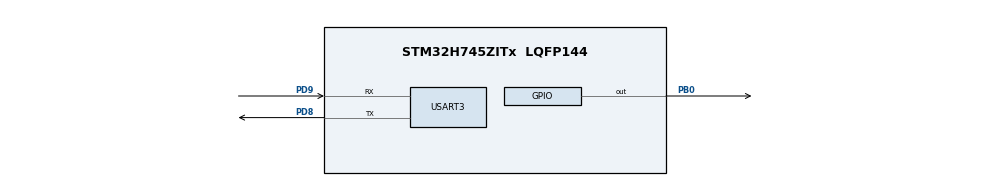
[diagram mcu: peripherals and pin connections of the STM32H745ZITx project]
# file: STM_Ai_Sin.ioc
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CORTEX_M7.CPU_DCache=Enabled
CORTEX_M7.CPU_ICache=Enabled
CORTEX_M7.default_mode_Activation=1
CortexM4.IPs=FATFS_M4\:I,FREERTOS_M4\:I,IWDG2\:I,RCC,WWDG2\:I,DMA,BDMA,MDMA,NVIC2\:I,ETH,DEBUG,PDM2PCM_M4\:I,PWR,RESMGR_UTILITY,SYS_M4\:I,USB_DEVICE_M4\:I,USB_HOST_M4\:I,CORTEX_M4\:I,GPIO,OPENAMP_M4\:I,VREFBUF,NUCLEO-H745ZI-Q\:I
CortexM7.IPs=FATFS_M7\:I,FREERTOS_M7\:I,IWDG1\:I,RCC\:I,WWDG1\:I,DMA\:I,BDMA\:I,MDMA\:I,NVIC1\:I,SYS\:I,USART3\:I,USB_OTG_FS\:I,USB_OTG_FS1\:I,ETH\:I,CORTEX_M7\:I,DEBUG\:I,PDM2PCM_M7\:I,PWR\:I,RESMGR_UTILITY\:I,USB_DEVICE_M7\:I,USB_HOST_M7\:I,GPIO\:I,OPENAMP_M7\:I,VREFBUF\:I,STMicroelectronics.X-CUBE-AI.10.2.0_M7\:I
CortexM7.Pins=PB0
Mcu.Family=STM32H7
Mcu.Name=STM32H745ZITx
Mcu.Package=LQFP144
NVIC1.PriorityGroup=NVIC_PRIORITYGROUP_4
NVIC2.PriorityGroup=NVIC_PRIORITYGROUP_4
PB0.PinAttribute=CortexM7
PB0.Signal=GPIO_Output
PB0.TagName=LD1
PB14.TagName=LD3
PC13.TagName=BUTTON
PD8.Mode=Asynchronous
PD8.PinAttribute=CortexM7
PD8.Signal=USART3_TX
PD8.TagName=VCP_TX
PD9.Mode=Asynchronous
PD9.PinAttribute=CortexM7
PD9.Signal=USART3_RX
PD9.TagName=VCP_RX
PE1.TagName=LD2
PH0-OSC_IN\ (PH0).Mode=HSE-External-Clock-Source
PH0-OSC_IN\ (PH0).PinAttribute=Free
PH0-OSC_IN\ (PH0).Signal=RCC_OSC_IN
ProjectManager.HeapSize=M4-0x200,M7-0x800
ProjectManager.StackSize=M4-0x400,M7-0x800
ProjectManager.TargetToolchain=STM32CubeIDE
RCC.ADCFreq_Value=16125000
RCC.APB1CLKDivider=RCC_HCLK_DIV4
RCC.APB1Freq_Value=16000000
RCC.APB2CLKDivider=RCC_HCLK_DIV2
RCC.APB2Freq_Value=16000000
RCC.APB3Freq_Value=16000000
RCC.APB4Freq_Value=16000000
RCC.CortexFreq_Value=64000000
RCC.D1CPRE=RCC_SYSCLK_DIV2
RCC.D1PPRE=RCC_APB3_DIV2
RCC.D2PPRE1=RCC_APB1_DIV2
RCC.D2PPRE2=RCC_APB2_DIV2
RCC.D3PPRE=RCC_APB4_DIV2
RCC.DIVM1=1
RCC.DIVM3=4
RCC.DIVN1=32
RCC.DIVN3=480
RCC.DIVQ1=20
RCC.DIVQ3=8
RCC.FLatency=FLASH_LATENCY_0
RCC.HCLKFreq_Value=32000000
RCC.HPRE=RCC_HCLK_DIV2
RCC.HSE_VALUE=8000000
RCC.PLL2FRACN=0
RCC.PLL3FRACN=0
RCC.PLLFRACN=0
RCC.PLLM=25
RCC.PLLMUL=RCC_PLL_MUL9
RCC.PLLN=432
RCC.PLLQ=9
RCC.PLLSourceVirtual=RCC_PLLSOURCE_HSE
RCC.PRESCALERUSB=RCC_USBCLKSOURCE_PLL_DIV1_5
RCC.PWR_Regulator_Voltage_Scale=PWR_REGULATOR_VOLTAGE_SCALE3
RCC.SYSCLKFreq_VALUE=128000000
RCC.SYSCLKSource=RCC_SYSCLKSOURCE_PLLCLK
RCC.SYSCLKSourceVirtual=RCC_SYSCLKSOURCE_PLLCLK
RCC.SupplySource=PWR_DIRECT_SMPS_SUPPLY
RCC.USBCLockSelection=RCC_USBCLKSOURCE_PLL3
RCC.USBFreq_Value=120000000
STMicroelectronics.X-CUBE-AI.10.2.0_M7.ActivationBufferSizeList=2068
STMicroelectronics.X-CUBE-AI.10.2.0_M7.ActivationBuffers=pool0
STMicroelectronics.X-CUBE-AI.10.2.0_M7.ActivationNames=pool0
STMicroelectronics.X-CUBE-AI.10.2.0_M7.ActivationSizes=AI_SIN_DATA_ACTIVATION_1_SIZE
STMicroelectronics.X-CUBE-AI.10.2.0_M7.HeapSize=0x800
STMicroelectronics.X-CUBE-AI.10.2.0_M7.InternalRamActivationBufferMaxSize=AI_SIN_DATA_ACTIVATIONS_SIZE
STMicroelectronics.X-CUBE-AI.10.2.0_M7.LatestDirectoryUsed-f092dfcc138bfa4fe736b48b7a4581510309fae710944b16eda435efedff7797=C\:\\Users\\lachiara\\Desktop\\Uni_Andrea\\Programmi
STMicroelectronics.X-CUBE-AI.10.2.0_M7.MaximumNumberOfInputLayer=1
STMicroelectronics.X-CUBE-AI.10.2.0_M7.MaximumNumberOfOutputLayer=1
STMicroelectronics.X-CUBE-AI.10.2.0_M7.MaximumSizeOfInputLayer=1
STMicroelectronics.X-CUBE-AI.10.2.0_M7.MaximumSizeOfOutputLayer=1
STMicroelectronics.X-CUBE-AI.10.2.0_M7.ModelActualCompression-f092dfcc138bfa4fe736b48b7a4581510309fae710944b16eda435efedff7797=0.0
STMicroelectronics.X-CUBE-AI.10.2.0_M7.ModelCompression-f092dfcc138bfa4fe736b48b7a4581510309fae710944b16eda435efedff7797=None
STMicroelectronics.X-CUBE-AI.10.2.0_M7.ModelFlashOccupation-f092dfcc138bfa4fe736b48b7a4581510309fae710944b16eda435efedff7797=15708
STMicroelectronics.X-CUBE-AI.10.2.0_M7.ModelHashList=f092dfcc138bfa4fe736b48b7a4581510309fae710944b16eda435efedff7797
STMicroelectronics.X-CUBE-AI.10.2.0_M7.ModelKind-f092dfcc138bfa4fe736b48b7a4581510309fae710944b16eda435efedff7797=TFLITE
STMicroelectronics.X-CUBE-AI.10.2.0_M7.ModelMacc-f092dfcc138bfa4fe736b48b7a4581510309fae710944b16eda435efedff7797=1793
STMicroelectronics.X-CUBE-AI.10.2.0_M7.ModelName-f092dfcc138bfa4fe736b48b7a4581510309fae710944b16eda435efedff7797=sin
STMicroelectronics.X-CUBE-AI.10.2.0_M7.ModelNameList=sin
STMicroelectronics.X-CUBE-AI.10.2.0_M7.ModelRamOccupation-f092dfcc138bfa4fe736b48b7a4581510309fae710944b16eda435efedff7797=2068
STMicroelectronics.X-CUBE-AI.10.2.0_M7.ModelStructureFile-f092dfcc138bfa4fe736b48b7a4581510309fae710944b16eda435efedff7797=C\:\\Users\\lachiara\\Desktop\\Uni_Andrea\\Programmi\\sin_model.tflite
STMicroelectronics.X-CUBE-AI.10.2.0_M7.ModelType-f092dfcc138bfa4fe736b48b7a4581510309fae710944b16eda435efedff7797=STM32Cube.AI MCU runtime
STMicroelectronics.X-CUBE-AI.10.2.0_M7.ReadyForCodeGeneration=true
STMicroelectronics.X-CUBE-AI.10.2.0_M7.StackSize=0x800
STMicroelectronics.X-CUBE-AI.10.2.0_M7.WorkingBufferStartAddrList=0xFFFFFFFF
STMicroelectronics.X-CUBE-AI.10.2.0_M7.XAaCUBEAaAICcArtificialOoIntelligenceJjCore=true
STMicroelectronics.X-CUBE-AI.10.2.0_M7.copyWeightToRam=false
STMicroelectronics.X-CUBE-AI.10.2.0_M7.copyWeightToRam-f092dfcc138bfa4fe736b48b7a4581510309fae710944b16eda435efedff7797=false
STMicroelectronics.X-CUBE-AI.10.2.0_M7.customLayerConfigEnabled=false
STMicroelectronics.X-CUBE-AI.10.2.0_M7.customLayerConfigEnabled-f092dfcc138bfa4fe736b48b7a4581510309fae710944b16eda435efedff7797=false
STMicroelectronics.X-CUBE-AI.10.2.0_M7.noOnnxIoTranspose=false
STMicroelectronics.X-CUBE-AI.10.2.0_M7.noOnnxIoTranspose-f092dfcc138bfa4fe736b48b7a4581510309fae710944b16eda435efedff7797=false
STMicroelectronics.X-CUBE-AI.10.2.0_M7.useInputAllocation=true
STMicroelectronics.X-CUBE-AI.10.2.0_M7.useInputAllocation-f092dfcc138bfa4fe736b48b7a4581510309fae710944b16eda435efedff7797=true
STMicroelectronics.X-CUBE-AI.10.2.0_M7.useOutputAllocation=true
STMicroelectronics.X-CUBE-AI.10.2.0_M7.useOutputAllocation-f092dfcc138bfa4fe736b48b7a4581510309fae710944b16eda435efedff7797=true
USART3.VirtualMode-Asynchronous=VM_ASYNC
VP_STMicroelectronics.X-CUBE-AI_M7_VS_ArtificialOoIntelligenceJjXAaCUBEAaAI_10.2.0.Mode=ArtificialOoIntelligenceJjXAaCUBEAaAI
VP_SYS_M4_VS_Systick.Mode=SysTick
board=NUCLEO-H745ZI-Q

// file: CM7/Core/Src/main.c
/* USER CODE BEGIN Header */
/**
  ******************************************************************************
  * @file           : main.c
  * @brief          : Main program body
  ******************************************************************************
  * @attention
  *
  * Copyright (c) 2026 STMicroelectronics.
  * All rights reserved.
  *
  * This software is licensed under terms that can be found in the LICENSE file
  * in the root directory of this software component.
  * If no LICENSE file comes with this software, it is provided AS-IS.
  *
  ******************************************************************************
  */
/* USER CODE END Header */
#include "main.h"
#include "usart.h"
#include "gpio.h"

/* USER CODE BEGIN Includes */
#include <stdio.h>
#include <stdlib.h>
#include "ai_platform.h"
#include "sin.h"
#include "sin_data.h"
/* USER CODE END Includes */

/* USER CODE BEGIN PD */

/* DUAL_CORE_BOOT_SYNC_SEQUENCE: Define for dual core boot synchronization    */
/*                             demonstration code based on hardware semaphore */
/* This define is present in both CM7/CM4 projects                            */
/* To comment when developping/debugging on a single core                     */
//#define DUAL_CORE_BOOT_SYNC_SEQUENCE

#if defined(DUAL_CORE_BOOT_SYNC_SEQUENCE)
#ifndef HSEM_ID_0
#define HSEM_ID_0 (0U) /* HW semaphore 0*/
#endif
#endif /* DUAL_CORE_BOOT_SYNC_SEQUENCE */

/* USER CODE END PD */

/* USER CODE BEGIN PV */
ai_handle network = AI_HANDLE_NULL;
ai_u8 activations[AI_SIN_DATA_ACTIVATIONS_SIZE];

// Buffer fisici per i dati (dove mettiamo i float)
static float in_data[AI_SIN_IN_1_SIZE];
static float out_data[AI_SIN_OUT_1_SIZE];

// Array di strutture ai_buffer (che CubeAI usa per leggere i dati)
static ai_buffer ai_input[AI_SIN_IN_NUM];
static ai_buffer ai_output[AI_SIN_OUT_NUM];
/* USER CODE END PV */

void SystemClock_Config(void);
static void MPU_Config(void);

int main(void)
{

/* USER CODE BEGIN Boot_Mode_Sequence_0 */
#if defined(DUAL_CORE_BOOT_SYNC_SEQUENCE)
  int32_t timeout;
#endif /* DUAL_CORE_BOOT_SYNC_SEQUENCE */
/* USER CODE END Boot_Mode_Sequence_0 */

  /* MPU Configuration--------------------------------------------------------*/
  MPU_Config();

  /* Enable the CPU Cache */

  /* Enable I-Cache---------------------------------------------------------*/
  SCB_EnableICache();

  /* Enable D-Cache---------------------------------------------------------*/
  SCB_EnableDCache();

/* USER CODE BEGIN Boot_Mode_Sequence_1 */
#if defined(DUAL_CORE_BOOT_SYNC_SEQUENCE)
  /* Wait until CPU2 boots and enters in stop mode or timeout*/
  timeout = 0xFFFF;
  while((__HAL_RCC_GET_FLAG(RCC_FLAG_D2CKRDY) != RESET) && (timeout-- > 0));
  if ( timeout < 0 )
  {
  Error_Handler();
  }
#endif /* DUAL_CORE_BOOT_SYNC_SEQUENCE */
/* USER CODE END Boot_Mode_Sequence_1 */
  /* MCU Configuration--------------------------------------------------------*/

  /* Reset of all peripherals, Initializes the Flash interface and the Systick. */
  HAL_Init();

  /* Configure the system clock */
  SystemClock_Config();
/* USER CODE BEGIN Boot_Mode_Sequence_2 */
#if defined(DUAL_CORE_BOOT_SYNC_SEQUENCE)
/* When system initialization is finished, Cortex-M7 will release Cortex-M4 by means of
HSEM notification */
/*HW semaphore Clock enable*/
__HAL_RCC_HSEM_CLK_ENABLE();
/*Take HSEM */
HAL_HSEM_FastTake(HSEM_ID_0);
/*Release HSEM in order to notify the CPU2(CM4)*/
HAL_HSEM_Release(HSEM_ID_0,0);
/* wait until CPU2 wakes up from stop mode */
timeout = 0xFFFF;
while((__HAL_RCC_GET_FLAG(RCC_FLAG_D2CKRDY) == RESET) && (timeout-- > 0));
if ( timeout < 0 )
{
Error_Handler();
}
#endif /* DUAL_CORE_BOOT_SYNC_SEQUENCE */
/* USER CODE END Boot_Mode_Sequence_2 */

  /* Initialize all configured peripherals */
  MX_GPIO_Init();
  MX_USART3_UART_Init();
  /* USER CODE BEGIN 2 */
  ai_error err;

  // 1. Crea l'istanza della rete
  err = ai_sin_create(&network, AI_SIN_DATA_CONFIG);
  if (err.type != AI_ERROR_NONE) {
	  printf("Errore creazione rete!\r\n");
	  Error_Handler();
  }

  // 2. Inizializza la rete (Aggiunti i puntini per le struct nidificate)
  const ai_network_params params = {
		  .params = AI_SIN_DATA_WEIGHTS(ai_sin_data_weights_get()),
		  .activations = AI_SIN_DATA_ACTIVATIONS(activations)
  };

  if (!ai_sin_init(network, &params)) {
	  printf("Errore inizializzazione rete!\r\n");
	  Error_Handler();
  }

  // 3. Collega i buffer della rete ai nostri array in_data e out_data
  ai_input[0] = ai_sin_inputs_get(network, NULL)[0];
  ai_output[0] = ai_sin_outputs_get(network, NULL)[0];
  ai_input[0].data = AI_HANDLE_PTR(in_data);
  ai_output[0].data = AI_HANDLE_PTR(out_data);

  printf("Rete neurale 'sin' pronta all'uso!\r\n");
  /* USER CODE END 2 */

  /* Infinite loop */
  /* USER CODE BEGIN WHILE */
  float input_valore = 0.0f;
  char rx_buffer[20]; // Buffer per salvare i tasti premuti
  uint8_t rx_index;
  uint8_t ch;

  while (1)
  {
	  printf("\r\nInserisci un angolo in radianti e premi INVIO: ");
	  fflush(stdout);

	  // Azzera le variabili per la nuova lettura
	  rx_index = 0;
	  ch = 0;

	  // 1. Loop di ricezione manuale (Infallibile)
	  while (1) {
		  // Aspetta 1 singolo carattere
		  HAL_UART_Receive(&huart3, &ch, 1, HAL_MAX_DELAY);

		  // Fai l'eco del carattere per vederlo su PuTTY
		  HAL_UART_Transmit(&huart3, &ch, 1, HAL_MAX_DELAY);

		  // Se premiamo Invio (\r o \n) usciamo dal ciclo
		  if (ch == '\r' || ch == '\n') {
			  rx_buffer[rx_index] = '\0'; // Chiudi la stringa
			  break;
		  }
		  // Altrimenti, se c'è spazio, salva il carattere
		  else if (rx_index < 19) {
			  rx_buffer[rx_index++] = (char)ch;
		  }
	  }
	  // 2. Converti il testo digitato in un numero decimale (float)
	  input_valore = atof(rx_buffer);

	  printf("\r\nInput ricevuto: %.2f. Calcolo...\r\n", input_valore);

	  // 3. Metti il dato nel buffer AI
	  in_data[0] = input_valore;

	  // 4. Esegui l'inferenza
	  ai_i32 n_batch = ai_sin_run(network, ai_input, ai_output);

	  if (n_batch != 1) {
		  printf("Errore durante l'inferenza!\r\n");
	  } else {
		  // 5. Leggi il risultato
		  float previsione = out_data[0];
		  printf("Risultato AI (Seno): %.4f\r\n", previsione);
	  }

    /* USER CODE END WHILE */

  }
}

void SystemClock_Config(void)
{
  RCC_OscInitTypeDef RCC_OscInitStruct = {0};
  RCC_ClkInitTypeDef RCC_ClkInitStruct = {0};

  /** Supply configuration update enable
  */
  HAL_PWREx_ConfigSupply(PWR_DIRECT_SMPS_SUPPLY);

  /** Configure the main internal regulator output voltage
  */
  __HAL_PWR_VOLTAGESCALING_CONFIG(PWR_REGULATOR_VOLTAGE_SCALE3);

  while(!__HAL_PWR_GET_FLAG(PWR_FLAG_VOSRDY)) {}

  /** Initializes the RCC Oscillators according to the specified parameters
  * in the RCC_OscInitTypeDef structure.
  */
  RCC_OscInitStruct.OscillatorType = RCC_OSCILLATORTYPE_HSE;
  RCC_OscInitStruct.HSEState = RCC_HSE_BYPASS;
  RCC_OscInitStruct.PLL.PLLState = RCC_PLL_ON;
  RCC_OscInitStruct.PLL.PLLSource = RCC_PLLSOURCE_HSE;
  RCC_OscInitStruct.PLL.PLLM = 1;
  RCC_OscInitStruct.PLL.PLLN = 32;
  RCC_OscInitStruct.PLL.PLLP = 2;
  RCC_OscInitStruct.PLL.PLLQ = 20;
  RCC_OscInitStruct.PLL.PLLR = 2;
  RCC_OscInitStruct.PLL.PLLRGE = RCC_PLL1VCIRANGE_3;
  RCC_OscInitStruct.PLL.PLLVCOSEL = RCC_PLL1VCOWIDE;
  RCC_OscInitStruct.PLL.PLLFRACN = 0;
  if (HAL_RCC_OscConfig(&RCC_OscInitStruct) != HAL_OK)
  {
    Error_Handler();
  }

  /** Initializes the CPU, AHB and APB buses clocks
  */
  RCC_ClkInitStruct.ClockType = RCC_CLOCKTYPE_HCLK|RCC_CLOCKTYPE_SYSCLK
                              |RCC_CLOCKTYPE_PCLK1|RCC_CLOCKTYPE_PCLK2
                              |RCC_CLOCKTYPE_D3PCLK1|RCC_CLOCKTYPE_D1PCLK1;
  RCC_ClkInitStruct.SYSCLKSource = RCC_SYSCLKSOURCE_PLLCLK;
  RCC_ClkInitStruct.SYSCLKDivider = RCC_SYSCLK_DIV2;
  RCC_ClkInitStruct.AHBCLKDivider = RCC_HCLK_DIV2;
  RCC_ClkInitStruct.APB3CLKDivider = RCC_APB3_DIV2;
  RCC_ClkInitStruct.APB1CLKDivider = RCC_APB1_DIV2;
  RCC_ClkInitStruct.APB2CLKDivider = RCC_APB2_DIV2;
  RCC_ClkInitStruct.APB4CLKDivider = RCC_APB4_DIV2;

  if (HAL_RCC_ClockConfig(&RCC_ClkInitStruct, FLASH_LATENCY_0) != HAL_OK)
  {
    Error_Handler();
  }
}

/* USER CODE BEGIN 4 */
int __io_putchar(int ch) {
  HAL_UART_Transmit(&huart3, (uint8_t *)&ch, 1, HAL_MAX_DELAY);
  return ch;
}

int __io_getchar(void) {
  uint8_t ch = 0;
  HAL_UART_Receive(&huart3, &ch, 1, HAL_MAX_DELAY);
  HAL_UART_Transmit(&huart3, &ch, 1, HAL_MAX_DELAY); // Echo per vedere cosa scrivi
  return ch;
}
/* USER CODE END 4 */

 /* MPU Configuration */

void MPU_Config(void)
{
  MPU_Region_InitTypeDef MPU_InitStruct = {0};

  /* Disables the MPU */
  HAL_MPU_Disable();

  /** Initializes and configures the Region and the memory to be protected
  */
  MPU_InitStruct.Enable = MPU_REGION_ENABLE;
  MPU_InitStruct.Number = MPU_REGION_NUMBER0;
  MPU_InitStruct.BaseAddress = 0x0;
  MPU_InitStruct.Size = MPU_REGION_SIZE_4GB;
  MPU_InitStruct.SubRegionDisable = 0x87;
  MPU_InitStruct.TypeExtField = MPU_TEX_LEVEL0;
  MPU_InitStruct.AccessPermission = MPU_REGION_NO_ACCESS;
  MPU_InitStruct.DisableExec = MPU_INSTRUCTION_ACCESS_DISABLE;
  MPU_InitStruct.IsShareable = MPU_ACCESS_SHAREABLE;
  MPU_InitStruct.IsCacheable = MPU_ACCESS_NOT_CACHEABLE;
  MPU_InitStruct.IsBufferable = MPU_ACCESS_NOT_BUFFERABLE;

  HAL_MPU_ConfigRegion(&MPU_InitStruct);
  /* Enables the MPU */
  HAL_MPU_Enable(MPU_PRIVILEGED_DEFAULT);

}

void Error_Handler(void)
{
  __disable_irq();
  while (1)
  {
  }
}
